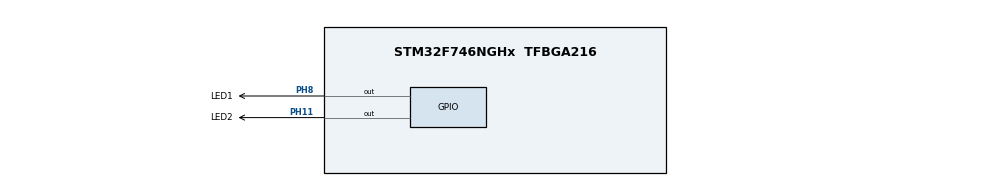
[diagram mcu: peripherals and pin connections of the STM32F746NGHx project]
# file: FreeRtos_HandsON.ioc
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FREERTOS.BinarySemaphores01=myBinarySem01,Dynamic,NULL
FREERTOS.INCLUDE_vTaskDelayUntil=1
FREERTOS.Tasks01=defaultTask,0,128,StartDefaultTask,Default,NULL,Dynamic,NULL,NULL;myTask02,-3,128,StartTask02,Default,NULL,Dynamic,NULL,NULL
FREERTOS.configUSE_NEWLIB_REENTRANT=1
IWDG.Reload=950
IWDG.Window=1000
Mcu.Family=STM32F7
Mcu.Name=STM32F746NGHx
Mcu.Package=TFBGA216
NVIC.PriorityGroup=NVIC_PRIORITYGROUP_4
PH0/OSC_IN.Mode=HSE-External-Oscillator
PH0/OSC_IN.Signal=RCC_OSC_IN
PH1/OSC_OUT.Mode=HSE-External-Oscillator
PH1/OSC_OUT.Signal=RCC_OSC_OUT
PH11.GPIO_Label=LED2
PH11.GPIO_PuPd=GPIO_PULLUP
PH11.GPIO_Speed=GPIO_SPEED_FREQ_HIGH
PH11.PinState=GPIO_PIN_SET
PH11.Signal=GPIO_Output
PH8.GPIO_Label=LED1
PH8.GPIO_PuPd=GPIO_PULLUP
PH8.GPIO_Speed=GPIO_SPEED_FREQ_HIGH
PH8.PinState=GPIO_PIN_SET
PH8.Signal=GPIO_Output
ProjectManager.HeapSize=0x200
ProjectManager.StackSize=0x400
ProjectManager.TargetToolchain=STM32CubeIDE
RCC.HSE_VALUE=25000000
RCC.HSI_VALUE=16000000
RCC.LSE_VALUE=32768
RCC.USBFreq_Value=96000000
RCC.VCOOutputFreq_Value=192000000
VP_FREERTOS_VS_CMSIS_V1.Mode=CMSIS_V1
VP_IWDG_VS_IWDG.Mode=IWDG_Activate
board=custom

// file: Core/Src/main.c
/* USER CODE BEGIN Header */
/**
  ******************************************************************************
  * @file           : main.c
  * @brief          : Main program body
  ******************************************************************************
  * @attention
  *
  * Copyright (c) 2023 STMicroelectronics.
  * All rights reserved.
  *
  * This software is licensed under terms that can be found in the LICENSE file
  * in the root directory of this software component.
  * If no LICENSE file comes with this software, it is provided AS-IS.
  *
  ******************************************************************************
  */
/* USER CODE END Header */
#include "main.h"
#include "cmsis_os.h"

IWDG_HandleTypeDef hiwdg;

osThreadId defaultTaskHandle;
osThreadId myTask02Handle;
osSemaphoreId myBinarySem01Handle;

void SystemClock_Config(void);
static void MX_GPIO_Init(void);
static void MX_IWDG_Init(void);
void StartDefaultTask(void const * argument);
void StartTask02(void const * argument);

/* USER CODE BEGIN 0 */

void StartDefaultTask(void const * argument);
void StartTask02(void const * argument);
/*
void vTask1(void *pvParameters)
{

	for( ; ; )
	{
		HAL_GPIO_WritePin(GPIOH, LED1_Pin, GPIO_PIN_RESET);

	}
}

void vTask2(void *pvParameters)
{
	TickType_t xLastWakeTime;
	const TickType_t xDelay250ms = pdMS_TO_TICKS( 250 );

	xLastWakeTime = xTaskGetTickCount();

	for( ; ; )
	{
		HAL_GPIO_WritePin(GPIOH, LED2_Pin, GPIO_PIN_RESET);

	    vTaskDelayUntil(&xLastWakeTime, xDelay250ms);

	}
}
*/

/* USER CODE END 0 */

int main(void)
{

  /* MCU Configuration--------------------------------------------------------*/

  /* Reset of all peripherals, Initializes the Flash interface and the Systick. */
  HAL_Init();

  /* Configure the system clock */
  SystemClock_Config();

  /* Initialize all configured peripherals */
  MX_GPIO_Init();
  MX_IWDG_Init();

  /* Create the semaphores(s) */
  /* definition and creation of myBinarySem01 */
  osSemaphoreDef(myBinarySem01);
  myBinarySem01Handle = osSemaphoreCreate(osSemaphore(myBinarySem01), 1);

  /* Create the thread(s) */
  /* definition and creation of defaultTask */
  osThreadDef(defaultTask, StartDefaultTask, osPriorityNormal, 0, 128);
  defaultTaskHandle = osThreadCreate(osThread(defaultTask), NULL);

  /* definition and creation of myTask02 */
  osThreadDef(myTask02, StartTask02, osPriorityRealtime, 0, 128);
  myTask02Handle = osThreadCreate(osThread(myTask02), NULL);

  /* USER CODE BEGIN RTOS_THREADS */
  /* add threads, ... */

/*  xTaskCreate(   StartDefaultTask,"Task1_LED1",1000,NULL,osPriorityRealtime,NULL );

  xTaskCreate (StartTask02, "Task2_LED2", 1000, NULL, osPriorityHigh, NULL); */ /* task created for second task*/

  for ( ; ;);  //executing the loop infinitely

  /* USER CODE END RTOS_THREADS */

  /* Start scheduler */
  osKernelStart();
  /* We should never get here as control is now taken by the scheduler */
  /* Infinite loop */
  while (1)
  {

  }
}

void SystemClock_Config(void)
{
  RCC_OscInitTypeDef RCC_OscInitStruct = {0};
  RCC_ClkInitTypeDef RCC_ClkInitStruct = {0};

  /** Configure the main internal regulator output voltage
  */
  __HAL_RCC_PWR_CLK_ENABLE();
  __HAL_PWR_VOLTAGESCALING_CONFIG(PWR_REGULATOR_VOLTAGE_SCALE3);

  /** Initializes the RCC Oscillators according to the specified parameters
  * in the RCC_OscInitTypeDef structure.
  */
  RCC_OscInitStruct.OscillatorType = RCC_OSCILLATORTYPE_HSI|RCC_OSCILLATORTYPE_LSI;
  RCC_OscInitStruct.HSIState = RCC_HSI_ON;
  RCC_OscInitStruct.HSICalibrationValue = RCC_HSICALIBRATION_DEFAULT;
  RCC_OscInitStruct.LSIState = RCC_LSI_ON;
  RCC_OscInitStruct.PLL.PLLState = RCC_PLL_NONE;
  if (HAL_RCC_OscConfig(&RCC_OscInitStruct) != HAL_OK)
  {
    Error_Handler();
  }

  /** Initializes the CPU, AHB and APB buses clocks
  */
  RCC_ClkInitStruct.ClockType = RCC_CLOCKTYPE_HCLK|RCC_CLOCKTYPE_SYSCLK
                              |RCC_CLOCKTYPE_PCLK1|RCC_CLOCKTYPE_PCLK2;
  RCC_ClkInitStruct.SYSCLKSource = RCC_SYSCLKSOURCE_HSI;
  RCC_ClkInitStruct.AHBCLKDivider = RCC_SYSCLK_DIV1;
  RCC_ClkInitStruct.APB1CLKDivider = RCC_HCLK_DIV1;
  RCC_ClkInitStruct.APB2CLKDivider = RCC_HCLK_DIV1;

  if (HAL_RCC_ClockConfig(&RCC_ClkInitStruct, FLASH_LATENCY_0) != HAL_OK)
  {
    Error_Handler();
  }
}

static void MX_IWDG_Init(void)
{

  hiwdg.Instance = IWDG;
  hiwdg.Init.Prescaler = IWDG_PRESCALER_4;
  hiwdg.Init.Window = 1000;
  hiwdg.Init.Reload = 950;
  if (HAL_IWDG_Init(&hiwdg) != HAL_OK)
  {
    Error_Handler();
  }

}

static void MX_GPIO_Init(void)
{
  GPIO_InitTypeDef GPIO_InitStruct = {0};

  /* GPIO Ports Clock Enable */
  __HAL_RCC_GPIOH_CLK_ENABLE();

  /*Configure GPIO pin Output Level */
  HAL_GPIO_WritePin(GPIOH, LED2_Pin|LED1_Pin, GPIO_PIN_SET);

  /*Configure GPIO pins : LED2_Pin LED1_Pin */
  GPIO_InitStruct.Pin = LED2_Pin|LED1_Pin;
  GPIO_InitStruct.Mode = GPIO_MODE_OUTPUT_PP;
  GPIO_InitStruct.Pull = GPIO_PULLUP;
  GPIO_InitStruct.Speed = GPIO_SPEED_FREQ_HIGH;
  HAL_GPIO_Init(GPIOH, &GPIO_InitStruct);

}

void StartDefaultTask(void const * argument)
{
  /* USER CODE BEGIN 5 */
  /* Infinite loop */
	osSemaphoreWait(myBinarySem01Handle, 250);

	for( ; ; )
	{
		HAL_GPIO_WritePin(GPIOH, LED1_Pin, GPIO_PIN_RESET);
	}
  /* USER CODE END 5 */
}

void StartTask02(void const * argument)
{
  /* USER CODE BEGIN StartTask02 */
  /* Infinite loop */
	TickType_t xLastWakeTime;
	const TickType_t xDelay250ms = pdMS_TO_TICKS( 250 );

	xLastWakeTime = xTaskGetTickCount();

	osSemaphoreRelease(myBinarySem01Handle);

	for( ; ; )
	{
		HAL_GPIO_WritePin(GPIOH, LED2_Pin, GPIO_PIN_RESET);

	    osDelayUntil(&xLastWakeTime, xDelay250ms);

	}
  /* USER CODE END StartTask02 */
}

void Error_Handler(void)
{
  __disable_irq();
  while (1)
  {
  }
}
